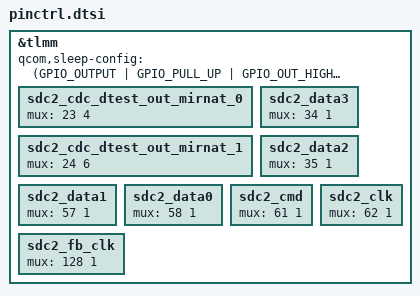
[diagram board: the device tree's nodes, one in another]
#include "gpio-dt.h"

/**
 *
 * NOTE: Every Dev team has to uncomment the respective PIN configuratoin.
 *
 */
&tlmm {
  //qup0_se0_l0: qup0_se0_l0 {
  //  mux = <0 1>;
  //};
  //ibi_i3c_qup0_se0_sda: ibi_i3c_qup0_se0_sda {
  //  mux = <0 2>;
  //};
  //aoss_cti_debug_data0: aoss_cti_debug_data0 {
  //  mux = <0 3>;
  //};
  //qup0_se0_l1: qup0_se0_l1 {
  //  mux = <1 1>;
  //};
  //ibi_i3c_qup0_se0_scl: ibi_i3c_qup0_se0_scl {
  //  mux = <1 2>;
  //};
  //aoss_cti_debug_data1: aoss_cti_debug_data1 {
  //  mux = <1 3>;
  //};
  //qup0_se0_l2: qup0_se0_l2 {
  //  mux = <2 1>;
  //};
  //qup0_se0_l3: qup0_se0_l3 {
  //  mux = <3 1>;
  //};
  //qup0_se1_l0: qup0_se1_l0 {
  //  mux = <4 1>;
  //};
  //ibi_i3c_qup0_se1_sda: ibi_i3c_qup0_se1_sda {
  //  mux = <4 2>;
  //};
  //aoss_cti_debug_data2: aoss_cti_debug_data2 {
  //  mux = <4 3>;
  //};
  //sd_write_protect: sd_write_protect {
  //  mux = <4 4>;
  //};
  //qdss_cti_trig0_in_mirb: qdss_cti_trig0_in_mirb {
  //  mux = <4 5>;
  //};
  //qup0_se1_l1: qup0_se1_l1 {
  //  mux = <5 1>;
  //};
  //ibi_i3c_qup0_se1_scl: ibi_i3c_qup0_se1_scl {
  //  mux = <5 2>;
  //};
  //aoss_cti_debug_data3: aoss_cti_debug_data3 {
  //  mux = <5 3>;
  //};
  //qdss_cti_trig0_out_mirb: qdss_cti_trig0_out_mirb {
  //  mux = <5 4>;
  //};
  //qup0_se1_l2: qup0_se1_l2 {
  //  mux = <6 1>;
  //};
  //qdss_cti_trig1_out_mirb: qdss_cti_trig1_out_mirb {
  //  mux = <6 2>;
  //};
  //qup0_se1_l3: qup0_se1_l3 {
  //  mux = <7 1>;
  //};
  //qdss_cti_trig1_in_mirb: qdss_cti_trig1_in_mirb {
  //  mux = <7 2>;
  //};
  //qup0_se2_l0: qup0_se2_l0 {
  //  mux = <8 1>;
  //};
  //do_not_expose_qup3_qspi_data_0: do_not_expose_qup3_qspi_data_0 {
  //  mux = <8 2>;
  //};
  //dbg_bus_out_loca_31: dbg_bus_out_loca_31 {
  //  mux = <8 3>;
  //};
  //phase_flag_status_loc_31: phase_flag_status_loc_31 {
  //  mux = <8 4>;
  //};
  //qup0_se2_l1: qup0_se2_l1 {
  //  mux = <9 1>;
  //};
  //do_not_expose_qup3_qspi_data_1: do_not_expose_qup3_qspi_data_1 {
  //  mux = <9 2>;
  //};
  //dbg_bus_out_loca_30: dbg_bus_out_loca_30 {
  //  mux = <9 3>;
  //};
  //phase_flag_status_loc_30: phase_flag_status_loc_30 {
  //  mux = <9 4>;
  //};
  //qup0_se2_l2: qup0_se2_l2 {
  //  mux = <10 1>;
  //};
  //qspi_clk: qspi_clk {
  //  mux = <10 2>;
  //};
  //qup0_se2_l3: qup0_se2_l3 {
  //  mux = <11 1>;
  //};
  //qspi_cs_n_0: qspi_cs_n_0 {
  //  mux = <11 2>;
  //};
  //dbg_bus_out_loca_29: dbg_bus_out_loca_29 {
  //  mux = <11 3>;
  //};
  //phase_flag_status_loc_29: phase_flag_status_loc_29 {
  //  mux = <11 4>;
  //};  
  //qup0_se2_l4: qup0_se2_l4 {
  //  mux = <12 1>;
  //};
  //qspi_cs_n_1: qspi_cs_n_1 {
  //  mux = <12 2>;
  //};
  //mdp_vsync0_out: mdp_vsync0_out {
  //  mux = <12 3>;
  //};
  //mdp_vsync1_out: mdp_vsync1_out {
  //  mux = <12 4>;
  //};
  //dbg_bus_out_loca_29: dbg_bus_out_loca_28 {
  //  mux = <12 5>;
  //};
  //phase_flag_status_loc_29: phase_flag_status_loc_28 {
  //  mux = <12 6>;
  //};
  //qup0_se2_l5: qup0_se2_l5 {
  //  mux = <13 1>;
  //};
  //do_not_expose_qup3_qspi_data_2: do_not_expose_qup3_qspi_data_2 {
  //  mux = <13 2>;
  //};
  //dbg_bus_out_loca_27: dbg_bus_out_loca_27 {
  //  mux = <13 3>;
  //};
  //phase_flag_status_loc_27: phase_flag_status_loc_27 {
  //  mux = <13 4>;
  //};
  //qup0_se2_l6: qup0_se2_l6 {
  //  mux = <14 1>;
  //};
  //do_not_expose_qup3_qspi_data_3: do_not_expose_qup3_qspi_data_3 {
  //  mux = <14 2>;
  //};
  //dbg_bus_out_loca_26: dbg_bus_out_loca_26 {
  //  mux = <14 3>;
  //};
  //phase_flag_status_loc_26: phase_flag_status_loc_26 {
  //  mux = <14 4>;
  //};
  //qup0_se3_l0: qup0_se3_l0 {
  //  mux = <15 1>;
  //};
  //i2s0_sck: i2s0_sck {
  //  mux = <15 2>;
  //};
  //dbg_bus_out_loca_25: dbg_bus_out_loca_25 {
  //  mux = <15 3>;
  //};
  //phase_flag_status_loc_25: phase_flag_status_loc_25 {
  //  mux = <15 4>;
  //};
  //qup0_se3_l1: qup0_se3_l1 {
  //  mux = <16 1>;
  //};
  //i2s0_data0: i2s0_data0 {
  //  mux = <16 2>;
  //};
  //dbg_bus_out_loca_24: dbg_bus_out_loca_24 {
  //  mux = <16 3>;
  //};
  //phase_flag_status_loc_24: phase_flag_status_loc_24 {
  //  mux = <16 4>;
  //};
  //qup0_se3_l2: qup0_se3_l2 {
  //  mux = <17 1>;
  //};
  //i2s0_data1: i2s0_data1 {
  //  mux = <17 2>;
  //};
  //tsense_pwm1_out_mir: tsense_pwm1_out_mir {
  //  mux = <17 3>;
  //};
  //tsense_pwm2_out_mir: tsense_pwm2_out_mir {
  //  mux = <17 4>;
  //};
  //qup0_se3_l3: qup0_se3_l3 {
  //  mux = <18 1>;
  //};
  //i2s0_ws: i2s0_ws {
  //  mux = <18 2>;
  //};
  //dbg_bus_out_loca_23: dbg_bus_out_loca_23 {
  //  mux = <18 3>;
  //};
  //phase_flag_status_loc_23: phase_flag_status_loc_23 {
  //  mux = <18 4>;
  //};
  //qup0_se4_l0: qup0_se4_l0 {
  //  mux = <19 1>;
  //};
  //mdp_vsync_s_mira: mdp_vsync_s_mira {
  //  mux = <19 2>;
  //};
  //gp_pdm_mira_0: gp_pdm_mira_0 {
  //  mux = <19 3>;
  //};
  //dbg_bus_out_locb_30: dbg_bus_out_locb_30 {
  //  mux = <19 4>;
  //};
  //qup0_se4_l1: qup0_se4_l1 {
  //  mux = <20 1>;
  //};
  //gp_pdm_mira_1: gp_pdm_mira_1 {
  //  mux = <20 2>;
  //};
  //dbg_bus_out_locb_11: dbg_bus_out_locb_11 {
  //  mux = <20 3>;
  //};
  //qup0_se4_l2: qup0_se4_l2 {
  //  mux = <21 1>;
  //};
  //gp_pdm_mira_2: gp_pdm_mira_2 {
  //  mux = <21 2>;
  //};
  //dbg_bus_out_locb_15: dbg_bus_out_locb_15 {
  //  mux = <21 3>;
  //};
  //qup0_se4_l3: qup0_se4_l3 {
  //  mux = <22 1>;
  //};
  //dbg_bus_out_locb_14: dbg_bus_out_locb_14 {
  //  mux = <22 2>;
  //};
  //qup0_se5_l0: qup0_se5_l0 {
  //  mux = <23 1>;
  //};
  //qup0_se3_l4: qup0_se3_l4 {
  //  mux = <23 2>;
  //};
  //audio_ext_mclk0: audio_ext_mclk0 {
  //  mux = <23 3>;
  //};
  sdc2_cdc_dtest_out_mirnat_0: sdc2_cdc_dtest_out_mirnat_0 {
    mux = <23 4>;
  };
  //atest_usb0_testdataout0_mirnat_0: atest_usb0_testdataout0_mirnat_0 {
  //  mux = <23 5>;
  //};
  //ddr_pxi0_test_tri_mirnat: ddr_pxi0_test_tri_mirnat {
  //  mux = <23 6>;
  //};
  //qup0_se5_l1: qup0_se5_l1 {
  //  mux = <24 1>;
  //};
  //qup0_se3_l5: qup0_se3_l5 {
  //  mux = <24 2>;
  //};
  //audio_ext_mclk1: audio_ext_mclk1 {
  //  mux = <24 3>;
  //};
  //audio_ref_clk: audio_ref_clk {
  //  mux = <24 4>;
  //};
  //dbg_out_clk: dbg_out_clk {
  //  mux = <24 5>;
  //};
  sdc2_cdc_dtest_out_mirnat_1: sdc2_cdc_dtest_out_mirnat_1 {
    mux = <24 6>;
  };
  //atest_usb0_testdataout0_mirnat_1: atest_usb0_testdataout0_mirnat_1 {
  //  mux = <24 7>;
  //};
  //ddr_pxi0_test_done_mirnat: ddr_pxi0_test_done_mirnat {
  //  mux = <24 8>;
  //};
  //qup0_se5_l2: qup0_se5_l2 {
  //  mux = <25 1>;
  //};
  //dbg_bus_out_locb_10: dbg_bus_out_locb_10 {
  //  mux = <25 2>;
  //};
  //qup0_se5_l3: qup0_se5_l3 {
  //  mux = <26 1>;
  //};
  //qup0_se3_l6: qup0_se3_l6 {
  //  mux = <26 2>;
  //};
  //pll_bist_sync: pll_bist_sync {
  //  mux = <26 3>;
  //};
  //dbg_bus_out_loca: dbg_bus_out_loca {
  //  mux = <26 4>;
  //};
  //phase_flag_status_loc: phase_flag_status_loc {
  //  mux = <26 5>;
  //};
  //qup0_se6_l0: qup0_se6_l0 {
  //  mux = <27 1>;
  //};
  //gp_mn: gp_mn {
  //  mux = <27 2>;
  //};
  //qup0_se6_l1: qup0_se6_l1 {
  //  mux = <28 1>;
  //};
  //gcc_gp2_clk_mirb: gcc_gp2_clk_mirb {
  //  mux = <28 2>;
  //};
  //qup0_se6_l2: qup0_se6_l2 {
  //  mux = <29 1>;
  //};
  //gcc_gp1_clk_mira: gcc_gp1_clk_mira {
  //  mux = <29 2>;
  //};
  //dbg_bus_out_locb_16: dbg_bus_out_locb_16 {
  //  mux = <29 3>;
  //};
  //qup0_se6_l3: qup0_se6_l3 {
  //  mux = <30 1>;
  //};
  //gcc_gp2_clk_mira: gcc_gp2_clk_mira {
  //  mux = <30 2>;
  //};
  //dbg_bus_out_locb_17: dbg_bus_out_locb_17 {
  //  mux = <30 3>;
  //};
  //qup0_se6_l4: qup0_se6_l4 {
  //  mux = <31 1>;
  //};
  //gcc_gp3_clk_mira: gcc_gp3_clk_mira {
  //  mux = <31 2>;
  //};
  //dbg_bus_out_locb_18: dbg_bus_out_locb_18 {
  //  mux = <31 3>;
  //};
  //qup1_se0_l0: qup1_se0_l0 {
  //  mux = <32 1>;
  //};
  //ibi_i3c_qup1_se0_sda: ibi_i3c_qup1_se0_sda {
  //  mux = <32 2>;
  //};
  //gcc_gp1_clk_mirb: gcc_gp1_clk_mirb {
  //  mux = <32 3>;
  //};
  //dbg_bus_out_locb: dbg_bus_out_locb {
  //  mux = <32 4>;
  //};
  //qup1_se0_l1: qup1_se0_l1 {
  //  mux = <33 1>;
  //};
  //ibi_i3c_qup1_se0_scl: ibi_i3c_qup1_se0_scl {
  //  mux = <33 2>;
  //};
  //gcc_gp3_clk_mirb: gcc_gp3_clk_mirb {
  //  mux = <33 3>;
  //};
  sdc2_data3: sdc2_data3 {
    mux = <34 1>;
  };
  sdc2_data2: sdc2_data2 {
    mux = <35 1>;
  };
  //qup1_se1_l0: qup1_se1_l0 {
  //  mux = <36 1>;
  //};
  //qup1_se2_l4: qup1_se2_l4 {
  //  mux = <36 2>;
  //};
  //qup1_se2_l4: qup1_se2_l4 {
  //  mux = <36 3>;
  //};
  //ibi_i3c_qup1_se1_sda: ibi_i3c_qup1_se1_sda {
  //  mux = <36 4>;
  //};
  //qup1_se1_l1: qup1_se1_l1 {
  //  mux = <37 1>;
  //};
  //qup1_se2_l5: qup1_se2_l5 {
  //  mux = <37 2>;
  //};
  //ibi_i3c_qup1_se1_scl: ibi_i3c_qup1_se1_scl {
  //  mux = <37 3>;
  //};
  //mdp_vsync_s_mirb: mdp_vsync_s_mirb {
  //  mux = <37 4>;
  //};
  //qup1_se1_l2: qup1_se1_l2 {
  //  mux = <38 1>;
  //};
  //qup1_se2_l6: qup1_se2_l6 {
  //  mux = <38 2>;
  //};
  //dbg_bus_out_loca_21: dbg_bus_out_loca_21 {
  //  mux = <38 3>;
  //};
  //phase_flag_status_loc_21: phase_flag_status_loc_21 {
  //  mux = <38 4>;
  //};
  //qup1_se1_l3: qup1_se1_l3 {
  //  mux = <39 1>;
  //};
  //dbg_bus_out_loca: dbg_bus_out_loca {
  //  mux = <39 3>;
  //};
  //phase_flag_status_loc: phase_flag_status_loc {
  //  mux = <39 4>;
  //};
  //qup1_se2_l0: qup1_se2_l0 {
  //  mux = <40 1>;
  //};
  //mdp_vsync2_out: mdp_vsync2_out {
  //  mux = <40 2>;
  //};
  //mdp_vsync3_out: mdp_vsync3_out {
  //  mux = <40 3>;
  //};
  //dbg_bus_out_loca_19: dbg_bus_out_loca_19 {
  //  mux = <40 4>;
  //};
  //phase_flag_status_loc_19: phase_flag_status_loc_19 {
  //  mux = <40 5>;
  //};
  //qdss_gpio_tracedata_loca_0: qdss_gpio_tracedata_loca_0 {
  //  mux = <40 6>;
  //};
  //qup1_se2_l1: qup1_se2_l1 {
  //  mux = <41 1>;
  //};
  //dbg_bus_out_loca_18: dbg_bus_out_loca_18 {
  //  mux = <41 2>;
  //};
  //phase_flag_status_loc_18: phase_flag_status_loc_18 {
  //  mux = <41 3>;
  //};
  //qdss_gpio_tracedata_loca_1: qdss_gpio_tracedata_loca_1 {
  //  mux = <41 4>;
  //};
  //qup1_se2_l2: qup1_se2_l2 {
  //  mux = <42 1>;
  //};
  //dbg_bus_out_loca_17: dbg_bus_out_loca_17 {
  //  mux = <42 2>;
  //};
  //phase_flag_status_loc_17: phase_flag_status_loc_17 {
  //  mux = <42 3>;
  //};
  //qdss_gpio_tracedata_loca_2: qdss_gpio_tracedata_loca_2 {
  //  mux = <42 4>;
  //};
  //qup1_se2_l3: qup1_se2_l3 {
  //  mux = <43 1>;
  //};
  //gp_pdm_mirb_0: gp_pdm_mirb_0 {
  //  mux = <43 2>;
  //};
  //dbg_bus_out_loca_16: dbg_bus_out_loca_16 {
  //  mux = <43 3>;
  //};
  //phase_flag_status_loc_16: phase_flag_status_loc_16 {
  //  mux = <43 4>;
  //};
  //qdss_gpio_tracedata_loca_3: qdss_gpio_tracedata_loca_3 {
  //  mux = <43 5>;
  //};
  //gp_pdm_mirb_1: gp_pdm_mirb_1 {
  //  mux = <44 1>;
  //};
  //dbg_bus_out_loca_15: dbg_bus_out_loca_15 {
  //  mux = <44 2>;
  //};
  //phase_flag_status_loc_15: phase_flag_status_loc_15 {
  //  mux = <44 3>;
  //};
  //qdss_cti_trig0_in_mira: qdss_cti_trig0_in_mira {
  //  mux = <44 4>;
  //};
  //atest_char_status_loc_0: atest_char_status_loc_0 {
  //  mux = <44 5>;
  //};
  //wcn_sw_ctrl: wcn_sw_ctrl {
  //  mux = <45 1>;
  //};
  //mdp_vsync_e: mdp_vsync_e {
  //  mux = <45 2>;
  //};
  //gp_pdm_mirb: gp_pdm_mirb {
  //  mux = <45 3>;
  //};
  //dbg_bus_out_loca: dbg_bus_out_loca {
  //  mux = <45 4>;
  //};
  //phase_flag_status_loc: phase_flag_status_loc {
  //  mux = <45 5>;
  //};
  //qdss_cti_trig1_in_mira: qdss_cti_trig1_in_mira {
  //  mux = <45 6>;
  //};
  //atest_char_status_loc: atest_char_status_loc {
  //  mux = <45 7>;
  //};
  //host2wlan_sol: host2wlan_sol {
  //  mux = <46 1>;
  //};
  //dbg_bus_out_loca_13: dbg_bus_out_loca_13 {
  //  mux = <46 2>;
  //};
  //phase_flag_status_loc_13: phase_flag_status_loc_13 {
  //  mux = <46 3>;
  //};
  //qdss_gpio_tracedata_loca_4: qdss_gpio_tracedata_loca_4 {
  //  mux = <46 4>;
  //};
  //atest_char_status_loc_2: atest_char_status_loc_2 {
  //  mux = <46 5>;
  //};
  //ddr_bist_stop: ddr_bist_stop {
  //  mux = <47 1>;
  //};
  //dbg_bus_out_loca_12: dbg_bus_out_loca_12 {
  //  mux = <47 2>;
  //};
  //phase_flag_status_loc_12: phase_flag_status_loc_12 {
  //  mux = <47 3>;
  //};
  //qdss_gpio_tracedata_loca_5: qdss_gpio_tracedata_loca_5 {
  //  mux = <47 4>;
  //};
  //atest_char_status_loc_3: atest_char_status_loc_3 {
  //  mux = <47 5>;
  //};
  //qup1_se4_l0: qup1_se4_l0 {
  //  mux = <48 1>;
  //};
  //dbg_bus_out_loca_11: dbg_bus_out_loca_11 {
  //  mux = <48 2>;
  //};
  //phase_flag_status_loc_11: phase_flag_status_loc_11 {
  //  mux = <48 3>;
  //};
  //qdss_gpio_tracedata_loca_6: qdss_gpio_tracedata_loca_6 {
  //  mux = <48 4>;
  //};
  //qup1_se4_l1: qup1_se4_l1 {
  //  mux = <49 1>;
  //};
  //dbg_bus_out_loca_10: dbg_bus_out_loca_10 {
  //  mux = <49 2>;
  //};
  //phase_flag_status_loc_10: phase_flag_status_loc_10 {
  //  mux = <49 3>;
  //};
  //qdss_gpio_tracedata_loca_7: qdss_gpio_tracedata_loca_7 {
  //  mux = <49 4>;
  //};
  //qup1_se4_l2: qup1_se4_l2 {
  //  mux = <50 1>;
  //};
  //qdss_gpio_tracedata_loca_8: qdss_gpio_tracedata_loca_8 {
  //  mux = <50 2>;
  //};
  //ddr_pxi1_test_tri_mirnat: ddr_pxi1_test_tri_mirnat {
  //  mux = <50 3>;
  //};
  //qup1_se4_l3: qup1_se4_l3 {
  //  mux = <51 1>;
  //};
  //qdss_gpio_tracedata_loca_9: qdss_gpio_tracedata_loca_9 {
  //  mux = <51 2>;
  //};
  //ddr_pxi1_test_done_mirnat: ddr_pxi1_test_done_mirnat {
  //  mux = <51 3>;
  //};
  //qup1_se4_l4: qup1_se4_l4 {
  //  mux = <52 1>;
  //};
  //wcn_sw_ctrl_wl_cx: wcn_sw_ctrl_wl_cx {
  //  mux = <52 2>;
  //};
  //qdss_gpio_tracedata_loca_10: qdss_gpio_tracedata_loca_10 {
  //  mux = <52 3>;
  //};
  //qup1_se4_l5: qup1_se4_l5 {
  //  mux = <53 1>;
  //};
  //qdss_gpio_tracedata_loca_11: qdss_gpio_tracedata_loca_11 {
  //  mux = <53 2>;
  //};
  //qup1_se4_l6: qup1_se4_l6 {
  //  mux = <54 1>;
  //};
  //qdss_cti_trig0_out_mira: qdss_cti_trig0_out_mira {
  //  mux = <54 2>;
  //};
  //qup1_se5_l0: qup1_se5_l0 {
  //  mux = <55 1>;
  //};
  //qup1_se6_l2_mira: qup1_se6_l2_mira {
  //  mux = <55 2>;
  //};
  //qup1_se5_l1: qup1_se5_l1 {
  //  mux = <56 1>;
  //};
  //qup1_se6_l3_mira: qup1_se6_l3_mira {
  //  mux = <56 2>;
  //};
  //vfr_0: vfr_0 {
  //  mux = <56 3>;
  //};
  //ddr_bist_fail: ddr_bist_fail {
  //  mux = <56 4>;
  //};
  sdc2_data1: sdc2_data1 {
    mux = <57 1>;
  };
  sdc2_data0: sdc2_data0 {
    mux = <58 1>;
  };
  //qup1_se6_l0: qup1_se6_l0 {
  //  mux = <59 1>;
  //};
  //grfc10: grfc10 {
  //  mux = <59 2>;
  //};
  //qup1_se5_l2: qup1_se5_l2 {
  //  mux = <59 3>;
  //};
  //qup1_se6_l1: qup1_se6_l1 {
  //  mux = <60 1>;
  //};
  //grfc11: grfc11 {
  //  mux = <60 2>;
  //};
  //qup1_se5_l3: qup1_se5_l3 {
  //  mux = <60 3>;
  //};
  //atest_usb0_atereset_mirnat: atest_usb0_atereset_mirnat {
  //  mux = <60 4>;
  //};
  sdc2_cmd: sdc2_cmd {
    mux = <61 1>;
  };
  sdc2_clk: sdc2_clk {
    mux = <62 1>;
  };
  //coex_uart1_tx: coex_uart1_tx {
  //  mux = <63 1>;
  //};
  //dbg_bus_out_loca_5: dbg_bus_out_loca_5 {
  //  mux = <63 2>;
  //};
  //phase_flag_status_loc_5: phase_flag_status_loc_5 {
  //  mux = <63 3>;
  //};
  //coex_uart1_rx: coex_uart1_rx {
  //  mux = <64 1>;
  //};
  //dbg_bus_out_loca_0: dbg_bus_out_loca_0 {
  //  mux = <64 2>;
  //};
  //phase_flag_status_loc_0: phase_flag_status_loc_0 {
  //  mux = <64 3>;
  //};
  //prng_rosc_test_out_0: prng_rosc_test_out_0 {
  //  mux = <66 1>;
  //};
  //dbg_bus_out_locb_26: dbg_bus_out_locb_26 {
  //  mux = <66 2>;
  //};
  //pcie0_clk_req_n: pcie0_clk_req_n {
  //  mux = <67 1>;
  //};
  //prng_rosc_test_out_1: prng_rosc_test_out_1 {
  //  mux = <67 2>;
  //};
  //dbg_bus_out_locb_24: dbg_bus_out_locb_24 {
  //  mux = <67 3>;
  //};
  //prng_rosc_test_out_2: prng_rosc_test_out_2 {
  //  mux = <68 1>;
  //};
  //dbg_bus_out_locb_27: dbg_bus_out_locb_27 {
  //  mux = <68 2>;
  //};
  //prng_rosc_test_out_3: prng_rosc_test_out_3 {
  //  mux = <69 1>;
  //};
  //dbg_bus_out_locb_9: dbg_bus_out_locb_9 {
  //  mux = <69 2>;
  //};
  //pcie1_clk_req_n: pcie1_clk_req_n {
  //  mux = <70 1>;
  //};
  //dbg_bus_out_locb_8: dbg_bus_out_locb_8 {
  //  mux = <70 2>;
  //};
  //dbg_bus_out_locb_7: dbg_bus_out_locb_7 {
  //  mux = <71 1>;
  //};
  //SDC1_RCLK: SDC1_RCLK {
  //  mux = <72 1>;
  //};
  //mdp_vsync_p_mirb: mdp_vsync_p_mirb {
  //  mux = <72 2>;
  //};
  //SDC1_DATA4: SDC1_DATA4 {
  //  mux = <73 1>;
  //};
  //SDC1_DATA5: SDC1_DATA5 {
  //  mux = <74 1>;
  //};
  //SDC1_DATA6: SDC1_DATA6 {
  //  mux = <75 1>;
  //};
  //dp0_hot_plug_detect: dp0_hot_plug_detect {
  //  mux = <75 2>;
  //};
  //SDC1_DATA7: SDC1_DATA7 {
  //  mux = <76 1>;
  //};
  //SDC1_CLK: SDC1_CLK {
  //  mux = <77 1>;
  //};
  //cci_timer0: cci_timer0 {
  //  mux = <77 2>;
  //};
  //SDC1_CMD: SDC1_CMD {
  //  mux = <78 1>;
  //};
  //tb_trig_sdc2: tb_trig_sdc2 {
  //  mux = <78 2>;
  //};
  //SDC1_DATA0: SDC1_DATA0 {
  //  mux = <79 1>;
  //};
  //SDC1_DATA1: SDC1_DATA1 {
  //  mux = <80 1>;
  //};
  //SDC1_DATA2: SDC1_DATA2 {
  //  mux = <81 1>;
  //};
  //SDC1_DATA3: SDC1_DATA3 {
  //  mux = <82 1>;
  //};
  //cam_mclk0: cam_mclk0 {
  //  mux = <83 1>;
  //};
  //cci_timer1: cci_timer1 {
  //  mux = <83 2>;
  //};
  //tmess_prng_rosc_test_out_1: tmess_prng_rosc_test_out_1 {
  //  mux = <83 3>;
  //};
  //qdss_gpio_tracedata_loca_12: qdss_gpio_tracedata_loca_12 {
  //  mux = <83 4>;
  //};
  //cam_mclk1: cam_mclk1 {
  //  mux = <84 1>;
  //};
  //cci_timer2: cci_timer2 {
  //  mux = <84 2>;
  //};
  //tmess_prng_rosc_test_out_2: tmess_prng_rosc_test_out_2 {
  //  mux = <84 3>;
  //};
  //qdss_gpio_tracedata_loca_13: qdss_gpio_tracedata_loca_13 {
  //  mux = <84 4>;
  //};
  //cam_mclk2: cam_mclk2 {
  //  mux = <85 1>;
  //};
  //cci_timer3: cci_timer3 {
  //  mux = <85 2>;
  //};
  //tmess_prng_rosc_test_out_3: tmess_prng_rosc_test_out_3 {
  //  mux = <85 3>;
  //};
  //qdss_gpio_tracedata_loca_14: qdss_gpio_tracedata_loca_14 {
  //  mux = <85 4>;
  //};
  //cam_mclk3: cam_mclk3 {
  //  mux = <86 1>;
  //};
  //cci_async_in0: cci_async_in0 {
  //  mux = <86 2>;
  //};
  //tmess_prng_rosc_test_out_0: tmess_prng_rosc_test_out_0 {
  //  mux = <86 3>;
  //};
  //qdss_gpio_tracedata_loca_15: qdss_gpio_tracedata_loca_15 {
  //  mux = <86 4>;
  //};
  //cam_mclk4: cam_mclk4 {
  //  mux = <87 1>;
  //};
  //tb_trig_sdc1: tb_trig_sdc1 {
  //  mux = <87 2>;
  //};
  //tgu_ch0_trigout: tgu_ch0_trigout {
  //  mux = <87 3>;
  //};
  //qdss_cti_trig1_out_mira: qdss_cti_trig1_out_mira {
  //  mux = <87 4>;
  //};
  //cci_i2c_sda0: cci_i2c_sda0 {
  //  mux = <88 1>;
  //};
  //tgu_ch1_trigout: tgu_ch1_trigout {
  //  mux = <88 2>;
  //};
  //dbg_bus_out_locb_6: dbg_bus_out_locb_6 {
  //  mux = <88 3>;
  //};
  //qdss_gpio_tracectl_loca: qdss_gpio_tracectl_loca {
  //  mux = <88 4>;
  //};
  //cci_i2c_scl0: cci_i2c_scl0 {
  //  mux = <89 1>;
  //};
  //dbg_bus_out_locb_5: dbg_bus_out_locb_5 {
  //  mux = <89 2>;
  //};
  //qdss_gpio_traceclk_loca: qdss_gpio_traceclk_loca {
  //  mux = <89 3>;
  //};
  //cci_i2c_sda1: cci_i2c_sda1 {
  //  mux = <90 1>;
  //};
  //qup1_se6_l2_mirb: qup1_se6_l2_mirb {
  //  mux = <90 2>;
  //};
  //dbg_bus_out_locb_4: dbg_bus_out_locb_4 {
  //  mux = <90 3>;
  //};
  //cci_i2c_scl1: cci_i2c_scl1 {
  //  mux = <91 1>;
  //};
  //qup1_se6_l3_mirb: qup1_se6_l3_mirb {
  //  mux = <91 2>;
  //};
  //dbg_bus_out_locb_3: dbg_bus_out_locb_3 {
  //  mux = <91 3>;
  //};
  //cci_i2c_sda2: cci_i2c_sda2 {
  //  mux = <92 1>;
  //};
  //qup1_se3_l0: qup1_se3_l0 {
  //  mux = <92 2>;
  //};
  //dbg_bus_out_locb_2: dbg_bus_out_locb_2 {
  //  mux = <92 3>;
  //};
  //cci_i2c_scl2: cci_i2c_scl2 {
  //  mux = <93 1>;
  //};
  //qup1_se3_l1: qup1_se3_l1 {
  //  mux = <93 2>;
  //};
  //dbg_bus_out_locb_1: dbg_bus_out_locb_1 {
  //  mux = <93 3>;
  //};
  //cci_i2c_sda3: cci_i2c_sda3 {
  //  mux = <94 1>;
  //};
  //qup1_se3_l2: qup1_se3_l2 {
  //  mux = <94 2>;
  //};
  //qup1_se0_l2: qup1_se0_l2 {
  //  mux = <94 3>;
  //};
  //dbg_bus_out_locb_0: dbg_bus_out_locb_0 {
  //  mux = <94 4>;
  //};
  //vsense_trigger_mirnat: vsense_trigger_mirnat {
  //  mux = <94 5>;
  //};
  //cci_i2c_scl3: cci_i2c_scl3 {
  //  mux = <95 1>;
  //};
  //qup1_se3_l3: qup1_se3_l3 {
  //  mux = <95 2>;
  //};
  //qup1_se0_l3: qup1_se0_l3 {
  //  mux = <95 3>;
  //};
  //uim0_data: uim0_data {
  //  mux = <96 1>;
  //};
  //uim0_clk: uim0_clk {
  //  mux = <97 1>;
  //};
  //uim0_reset: uim0_reset {
  //  mux = <98 1>;
  //};
  //uim0_present: uim0_present {
  //  mux = <99 1>;
  //};
  //uim1_data_mirb: uim1_data_mirb {
  //  mux = <100 1>;
  //};
  //uim1_clk_mirb: uim1_clk_mirb {
  //  mux = <101 1>;
  //};
  //uim1_reset_mirb: uim1_reset_mirb {
  //  mux = <102 1>;
  //};
  //uim1_present_mirb: uim1_present_mirb {
  //  mux = <103 1>;
  //};
  //qlink0_request: qlink0_request {
  //  mux = <104 1>;
  //};
  //qlink0_enable: qlink0_enable {
  //  mux = <105 1>;
  //};
  //qlink0_wmss_reset_n: qlink0_wmss_reset_n {
  //  mux = <106 1>;
  //};
  //qlink1_request: qlink1_request {
  //  mux = <107 1>;
  //};
  //qlink1_enable: qlink1_enable {
  //  mux = <108 1>;
  //};
  //qlink1_wmss_reset_n: qlink1_wmss_reset_n {
  //  mux = <109 1>;
  //};
  //uim1_data_mira: uim1_data_mira {
  //  mux = <110 1>;
  //};
  //uim1_clk_mira: uim1_clk_mira {
  //  mux = <111 1>;
  //};
  //uim1_reset_mira: uim1_reset_mira {
  //  mux = <112 1>;
  //};
  //uim1_present_mira: uim1_present_mira {
  //  mux = <113 1>;
  //};
  //rffe0_clk: rffe0_clk {
  //  mux = <114 1>;
  //};
  //grfc0: grfc0 {
  //  mux = <114 2>;
  //};
  //rffe0_data: rffe0_data {
  //  mux = <115 1>;
  //};
  //grfc1: grfc1 {
  //  mux = <115 2>;
  //};
  //rffe1_clk: rffe1_clk {
  //  mux = <116 1>;
  //};
  //grfc2: grfc2 {
  //  mux = <116 2>;
  //};
  //rffe1_data: rffe1_data {
  //  mux = <117 1>;
  //};
  //grfc3: grfc3 {
  //  mux = <117 2>;
  //};
  //grfc4: grfc4 {
  //  mux = <118 1>;
  //};
  //rffe2_clk: rffe2_clk {
  //  mux = <118 2>;
  //};
  //grfc5: grfc5 {
  //  mux = <119 1>;
  //};
  //rffe2_data: rffe2_data {
  //  mux = <119 2>;
  //};
  //grfc6: grfc6 {
  //  mux = <120 1>;
  //};
  //rffe3_clk: rffe3_clk {
  //  mux = <120 2>;
  //};
  //grfc7: grfc7 {
  //  mux = <121 1>;
  //};
  //rffe3_data: rffe3_data {
  //  mux = <121 2>;
  //};
  //rffe4_clk: rffe4_clk {
  //  mux = <122 1>;
  //};
  //grfc8: grfc8 {
  //  mux = <122 2>;
  //};
  //rffe4_data: rffe4_data {
  //  mux = <123 1>;
  //};
  //grfc9: grfc9 {
  //  mux = <123 2>;
  //};
  //nav_gpio0: nav_gpio0 {
  //  mux = <124 1>;
  //};
  //nav_gpio1: nav_gpio1 {
  //  mux = <125 1>;
  //};
  //grfc0_mira: grfc0_mira {
  //  mux = <126 1>;
  //};
  //nav_gpio2: nav_gpio2 {
  //  mux = <126 2>;
  //};
  //vfr_1: vfr_1 {
  //  mux = <126 3>;
  //};
  //grfc12: grfc12 {
  //  mux = <127 1>;
  //};
  //dbg_bus_out_loca_9: dbg_bus_out_loca_9 {
  //  mux = <127 2>;
  //};
  //phase_flag_status_loc_9: phase_flag_status_loc_9 {
  //  mux = <127 3>;
  //};
  sdc2_fb_clk: sdc2_fb_clk {
    mux = <128 1>;
  };
  //mdp_vsync_p_mira: mdp_vsync_p_mira {
  //  mux = <130 1>;
  //};
  //usb0_phy_ps: usb0_phy_ps {
  //  mux = <131 1>;
  //};
  //ddr_bist_start: ddr_bist_start {
  //  mux = <133 1>;
  //};
  //dbg_bus_out_loca_8: dbg_bus_out_loca_8 {
  //  mux = <138 1>;
  //};
  //phase_flag_status_loc_8: phase_flag_status_loc_8 {
  //  mux = <138 2>;
  //};
  //qdss_gpio_tracedata_locb_12: qdss_gpio_tracedata_locb_12 {
  //  mux = <138 3>;
  //};
  //dbg_bus_out_loca_7: dbg_bus_out_loca_7 {
  //  mux = <139 1>;
  //};
  //phase_flag_status_loc_7: phase_flag_status_loc_7 {
  //  mux = <139 2>;
  //};
  //qdss_gpio_tracedata_locb_13: qdss_gpio_tracedata_locb_13 {
  //  mux = <139 3>;
  //};
  //dbg_bus_out_loca_6: dbg_bus_out_loca_6 {
  //  mux = <140 1>;
  //};
  //phase_flag_status_loc_6: phase_flag_status_loc_6 {
  //  mux = <140 2>;
  //};
  //qdss_gpio_tracedata_locb_14: qdss_gpio_tracedata_locb_14 {
  //  mux = <140 3>;
  //};
  //jitter_bist_ref_clk: jitter_bist_ref_clk {
  //  mux = <141 1>;
  //};
  //qdss_gpio_tracedata_locb_15: qdss_gpio_tracedata_locb_15 {
  //  mux = <141 2>;
  //};
  //dbg_bus_out_loca_4: dbg_bus_out_loca_4 {
  //  mux = <142 1>;
  //};
  //phase_flag_status_loc_4: phase_flag_status_loc_4 {
  //  mux = <142 2>;
  //};
  //dbg_bus_out_loca_3: dbg_bus_out_loca_3 {
  //  mux = <143 1>;
  //};
  //phase_flag_status_loc_3: phase_flag_status_loc_3 {
  //  mux = <143 2>;
  //};
  //dbg_bus_out_loca_1: dbg_bus_out_loca_1 {
  //  mux = <144 1>;
  //};
  //phase_flag_status_loc_1: phase_flag_status_loc_1 {
  //  mux = <144 2>;
  //};
  //dbg_bus_out_locb_29: dbg_bus_out_locb_29 {
  //  mux = <145 1>;
  //};
  //dbg_bus_out_loca_2: dbg_bus_out_loca_2 {
  //  mux = <147 1>;
  //};
  //phase_flag_status_loc_2: phase_flag_status_loc_2 {
  //  mux = <147 2>;
  //};
  //dbg_bus_out_locb_13: dbg_bus_out_locb_13 {
  //  mux = <149 1>;
  //};
  //qdss_gpio_tracedata_locb_10: qdss_gpio_tracedata_locb_10 {
  //  mux = <149 2>;
  //};
  //sdc1_cdc_dtest_out_mirnat_0: sdc1_cdc_dtest_out_mirnat_0 {
  //  mux = <149 3>;
  //};
  //dbg_bus_out_locb_12: dbg_bus_out_locb_12 {
  //  mux = <150 1>;
  //};
  //qdss_gpio_tracedata_locb_11: qdss_gpio_tracedata_locb_11 {
  //  mux = <150 2>;
  //};
  //sdc1_cdc_dtest_out_mirnat_1: sdc1_cdc_dtest_out_mirnat_1 {
  //  mux = <150 3>;
  //};
  //sdc1_cdc_dtest_out_mir_1: sdc1_cdc_dtest_out_mir_1 {
  //  mux = <150 1>;
  //};
  //dbg_bus_out_locb_23: dbg_bus_out_locb_23 {
  //  mux = <151 1>;
  //};
  //dbg_bus_out_locb_22: dbg_bus_out_locb_22 {
  //  mux = <152 1>;
  //};
  //dbg_bus_out_locb_21: dbg_bus_out_locb_21 {
  //  mux = <153 1>;
  //};
  //dbg_bus_out_locb_20: dbg_bus_out_locb_20 {
  //  mux = <154 1>;
  //};
  //dbg_bus_out_locb_31: dbg_bus_out_locb_31 {
  //  mux = <155 1>;
  //};
  //qdss_gpio_traceclk_locb: qdss_gpio_traceclk_locb {
  //  mux = <155 2>;
  //};
  //dbg_bus_out_locb_28: dbg_bus_out_locb_28 {
  //  mux = <156 1>;
  //};
  //qdss_gpio_tracectl_locb: qdss_gpio_tracectl_locb {
  //  mux = <156 2>;
  //};
  //dbg_bus_out_locb_25: dbg_bus_out_locb_25 {
  //  mux = <157 1>;
  //};
  //qdss_gpio_tracedata_locb_0: qdss_gpio_tracedata_locb_0 {
  //  mux = <157 2>;
  //};
  //qdss_gpio_tracedata_locb_1: qdss_gpio_tracedata_locb_1 {
  //  mux = <158 1>;
  //};
  //qdss_gpio_tracedata_locb_2: qdss_gpio_tracedata_locb_2 {
  //  mux = <159 1>;
  //};
  //qdss_gpio_tracedata_locb_3: qdss_gpio_tracedata_locb_3 {
  //  mux = <160 1>;
  //};
  //qdss_gpio_tracedata_locb_4: qdss_gpio_tracedata_locb_4 {
  //  mux = <161 1>;
  //};
  //qdss_gpio_tracedata_locb_5: qdss_gpio_tracedata_locb_5 {
  //  mux = <162 1>;
  //};
  //qdss_gpio_tracedata_locb_6: qdss_gpio_tracedata_locb_6 {
  //  mux = <163 1>;
  //};
  //qdss_gpio_tracedata_locb_7: qdss_gpio_tracedata_locb_7 {
  //  mux = <164 1>;
  //};
  //qdss_gpio_tracedata_locb_8: qdss_gpio_tracedata_locb_8 {
  //  mux = <165 1>;
  //};
  //qdss_gpio_tracedata_locb_9: qdss_gpio_tracedata_locb_9 {
  //  mux = <166 1>;
  //};
};

&tlmm {
  qcom,sleep-config   =  <
(GPIO_OUTPUT | GPIO_PULL_UP | GPIO_OUT_HIGH | GPIO_PRG_YES)	/* GPIO_0 */
(GPIO_OUTPUT | GPIO_PULL_UP | GPIO_OUT_HIGH | GPIO_PRG_YES)	/* GPIO_1 */
(GPIO_INPUT | GPIO_PULL_DOWN | GPIO_OUT_LOW | GPIO_PRG_NO)	/* GPIO_2 */
(GPIO_INPUT | GPIO_PULL_DOWN | GPIO_OUT_LOW | GPIO_PRG_NO)	/* GPIO_3 */
(GPIO_OUTPUT | GPIO_PULL_UP | GPIO_OUT_HIGH | GPIO_PRG_YES)	/* GPIO_4 */
(GPIO_OUTPUT | GPIO_PULL_UP | GPIO_OUT_HIGH | GPIO_PRG_YES)	/* GPIO_5 */
(GPIO_INPUT  | GPIO_PULL_DOWN | GPIO_OUT_LOW | GPIO_PRG_NO)	/* GPIO_6 */
(GPIO_INPUT | GPIO_PULL_DOWN | GPIO_OUT_LOW | GPIO_PRG_NO)	/* GPIO_7 */
(GPIO_INPUT | GPIO_PULL_DOWN | GPIO_OUT_LOW | GPIO_PRG_NO)	/* GPIO_8 */

(GPIO_INPUT | GPIO_PULL_DOWN | GPIO_OUT_LOW | GPIO_PRG_NO)	/* GPIO_9 */
(GPIO_INPUT | GPIO_PULL_DOWN | GPIO_OUT_LOW | GPIO_PRG_NO)	/* GPIO_10 */
(GPIO_INPUT | GPIO_PULL_DOWN | GPIO_OUT_LOW | GPIO_PRG_NO)	/* GPIO_11 */
(GPIO_INPUT | GPIO_PULL_DOWN | GPIO_OUT_LOW | GPIO_PRG_NO)	/* GPIO_12 */
(GPIO_INPUT | GPIO_PULL_DOWN | GPIO_OUT_LOW | GPIO_PRG_NO)	/* GPIO_13 */
(GPIO_INPUT | GPIO_PULL_DOWN | GPIO_OUT_LOW | GPIO_PRG_NO)	/* GPIO_14 */
(GPIO_INPUT | GPIO_PULL_DOWN | GPIO_OUT_LOW | GPIO_PRG_NO)	/* GPIO_15 */
(GPIO_INPUT | GPIO_PULL_DOWN | GPIO_OUT_LOW | GPIO_PRG_NO)	/* GPIO_16 */
(GPIO_INPUT | GPIO_PULL_DOWN | GPIO_OUT_LOW | GPIO_PRG_NO)	/* GPIO_17 */
(GPIO_INPUT | GPIO_PULL_DOWN | GPIO_OUT_LOW | GPIO_PRG_NO)	/* GPIO_18 */

(GPIO_INPUT | GPIO_PULL_DOWN | GPIO_OUT_LOW | GPIO_PRG_NO)	/* GPIO_19 */
(GPIO_INPUT | GPIO_PULL_DOWN | GPIO_OUT_LOW | GPIO_PRG_NO)	/* GPIO_20 */
(GPIO_INPUT | GPIO_PULL_DOWN | GPIO_OUT_LOW | GPIO_PRG_NO)	/* GPIO_21 */
(GPIO_INPUT | GPIO_PULL_DOWN | GPIO_OUT_LOW | GPIO_PRG_NO)	/* GPIO_22 */
(GPIO_INPUT | GPIO_PULL_DOWN | GPIO_OUT_LOW | GPIO_PRG_NO)	/* GPIO_23 */
(GPIO_INPUT | GPIO_PULL_DOWN | GPIO_OUT_LOW | GPIO_PRG_NO)	/* GPIO_24 */
(GPIO_OUTPUT | GPIO_PULL_UP | GPIO_OUT_HIGH | GPIO_PRG_YES)	/* GPIO_25 */
(GPIO_INPUT | GPIO_PULL_DOWN | GPIO_OUT_LOW | GPIO_PRG_NO)	/* GPIO_26 */
(GPIO_OUTPUT | GPIO_PULL_UP | GPIO_OUT_HIGH | GPIO_PRG_YES)	/* GPIO_27 */
(GPIO_OUTPUT | GPIO_PULL_UP | GPIO_OUT_HIGH | GPIO_PRG_YES)	/* GPIO_28 */

(GPIO_OUTPUT | GPIO_PULL_UP | GPIO_OUT_HIGH | GPIO_PRG_YES)	/* GPIO_29 */
(GPIO_OUTPUT | GPIO_PULL_UP | GPIO_OUT_HIGH | GPIO_PRG_YES)	/* GPIO_30 */
(GPIO_INPUT | GPIO_PULL_DOWN | GPIO_OUT_LOW | GPIO_PRG_NO)	/* GPIO_31 */
(GPIO_OUTPUT | GPIO_PULL_UP | GPIO_OUT_HIGH | GPIO_PRG_YES)	/* GPIO_32 */
(GPIO_OUTPUT | GPIO_PULL_UP | GPIO_OUT_HIGH | GPIO_PRG_YES)	/* GPIO_33 */
(GPIO_INPUT | GPIO_PULL_DOWN | GPIO_OUT_LOW | GPIO_PRG_NO)	/* GPIO_34 */
(GPIO_INPUT | GPIO_PULL_DOWN | GPIO_OUT_LOW | GPIO_PRG_NO)	/* GPIO_35 */
(GPIO_INPUT | GPIO_PULL_DOWN | GPIO_OUT_LOW | GPIO_PRG_NO)	/* GPIO_36 */
(GPIO_INPUT | GPIO_PULL_DOWN | GPIO_OUT_LOW | GPIO_PRG_NO)	/* GPIO_37 */
(GPIO_INPUT | GPIO_PULL_DOWN | GPIO_OUT_LOW | GPIO_PRG_NO)	/* GPIO_38 */

(GPIO_INPUT | GPIO_PULL_DOWN | GPIO_OUT_LOW | GPIO_PRG_NO)	/* GPIO_39 */
(GPIO_INPUT | GPIO_PULL_DOWN | GPIO_OUT_LOW | GPIO_PRG_NO)	/* GPIO_40 */
(GPIO_INPUT | GPIO_PULL_DOWN | GPIO_OUT_LOW | GPIO_PRG_NO)	/* GPIO_41 */
(GPIO_INPUT | GPIO_PULL_DOWN | GPIO_OUT_LOW | GPIO_PRG_NO)	/* GPIO_42 */
(GPIO_INPUT | GPIO_PULL_DOWN | GPIO_OUT_LOW | GPIO_PRG_NO)	/* GPIO_43 */
(GPIO_INPUT | GPIO_PULL_DOWN | GPIO_OUT_LOW | GPIO_PRG_NO)	/* GPIO_44 */
(GPIO_INPUT | GPIO_PULL_DOWN | GPIO_OUT_LOW | GPIO_PRG_NO)	/* GPIO_45 */
(GPIO_INPUT | GPIO_PULL_DOWN | GPIO_OUT_LOW | GPIO_PRG_NO)	/* GPIO_46 */
(GPIO_INPUT | GPIO_PULL_DOWN | GPIO_OUT_LOW | GPIO_PRG_NO)	/* GPIO_47 */
(GPIO_INPUT | GPIO_PULL_DOWN | GPIO_OUT_LOW | GPIO_PRG_NO)	/* GPIO_48 */

(GPIO_INPUT | GPIO_PULL_DOWN | GPIO_OUT_LOW | GPIO_PRG_NO)	/* GPIO_49 */
(GPIO_OUTPUT | GPIO_PULL_UP | GPIO_OUT_HIGH | GPIO_PRG_YES)	/* GPIO_50 */
(GPIO_INPUT | GPIO_PULL_DOWN | GPIO_OUT_LOW | GPIO_PRG_NO)	/* GPIO_51 */
(GPIO_INPUT | GPIO_PULL_DOWN | GPIO_OUT_LOW | GPIO_PRG_NO)	/* GPIO_52 */
(GPIO_INPUT | GPIO_PULL_DOWN | GPIO_OUT_LOW | GPIO_PRG_NO)	/* GPIO_53 */
(GPIO_INPUT | GPIO_PULL_DOWN | GPIO_OUT_LOW | GPIO_PRG_NO)	/* GPIO_54 */
(GPIO_INPUT | GPIO_PULL_DOWN | GPIO_OUT_LOW | GPIO_PRG_NO)	/* GPIO_55 */
(GPIO_INPUT | GPIO_PULL_DOWN | GPIO_OUT_LOW | GPIO_PRG_NO)	/* GPIO_56 */
(GPIO_INPUT | GPIO_PULL_DOWN | GPIO_OUT_LOW | GPIO_PRG_NO)	/* GPIO_57 */
(GPIO_INPUT | GPIO_PULL_DOWN | GPIO_OUT_LOW | GPIO_PRG_NO)	/* GPIO_58 */

(GPIO_INPUT | GPIO_PULL_DOWN | GPIO_OUT_LOW | GPIO_PRG_NO)	/* GPIO_59 */
(GPIO_INPUT | GPIO_PULL_DOWN | GPIO_OUT_LOW | GPIO_PRG_NO)	/* GPIO_60 */
(GPIO_INPUT | GPIO_PULL_DOWN | GPIO_OUT_LOW | GPIO_PRG_NO)	/* GPIO_61 */
(GPIO_INPUT | GPIO_PULL_DOWN | GPIO_OUT_LOW | GPIO_PRG_NO)	/* GPIO_62 */
(GPIO_OUTPUT | GPIO_PULL_UP | GPIO_OUT_HIGH | GPIO_PRG_YES)	/* GPIO_63 */
(GPIO_INPUT | GPIO_NO_PULL | GPIO_OUT_LOW | GPIO_PRG_YES)   /* GPIO_64 */
(GPIO_INPUT | GPIO_NO_PULL | GPIO_OUT_LOW | GPIO_PRG_YES)	  /* GPIO_65 */
(GPIO_INPUT | GPIO_PULL_DOWN | GPIO_OUT_LOW | GPIO_PRG_NO)	/* GPIO_66 */
(GPIO_OUTPUT | GPIO_PULL_UP | GPIO_OUT_HIGH | GPIO_PRG_YES)	/* GPIO_67 */
(GPIO_OUTPUT | GPIO_PULL_UP | GPIO_OUT_HIGH | GPIO_PRG_YES)	/* GPIO_68 */

(GPIO_OUTPUT | GPIO_NO_PULL | GPIO_OUT_LOW | GPIO_PRG_YES)	/* GPIO_69 */
(GPIO_INPUT | GPIO_NO_PULL | GPIO_OUT_LOW | GPIO_PRG_YES)	  /* GPIO_70 */
(GPIO_OUTPUT | GPIO_NO_PULL | GPIO_OUT_LOW | GPIO_PRG_YES)	/* GPIO_71 */
(GPIO_INPUT | GPIO_PULL_DOWN | GPIO_OUT_LOW | GPIO_PRG_NO)	/* GPIO_72 */
(GPIO_INPUT | GPIO_NO_PULL | GPIO_OUT_LOW | GPIO_PRG_YES)	  /* GPIO_73 */
(GPIO_INPUT | GPIO_NO_PULL | GPIO_OUT_LOW | GPIO_PRG_YES)	  /* GPIO_74 */
(GPIO_INPUT | GPIO_PULL_DOWN | GPIO_OUT_LOW | GPIO_PRG_NO)	/* GPIO_75 */
(GPIO_INPUT | GPIO_PULL_DOWN | GPIO_OUT_LOW | GPIO_PRG_NO)	/* GPIO_76 */
(GPIO_INPUT | GPIO_PULL_DOWN | GPIO_OUT_LOW | GPIO_PRG_NO)	/* GPIO_77 */
(GPIO_INPUT | GPIO_PULL_DOWN | GPIO_OUT_LOW | GPIO_PRG_NO)	/* GPIO_78 */

(GPIO_INPUT | GPIO_PULL_DOWN | GPIO_OUT_LOW | GPIO_PRG_NO)	/* GPIO_79 */
(GPIO_INPUT | GPIO_PULL_DOWN | GPIO_OUT_LOW | GPIO_PRG_NO)	/* GPIO_80 */
(GPIO_INPUT | GPIO_PULL_DOWN | GPIO_OUT_LOW | GPIO_PRG_NO)	/* GPIO_81 */
(GPIO_INPUT | GPIO_NO_PULL | GPIO_OUT_LOW | GPIO_PRG_YES)	  /* GPIO_82 */
(GPIO_INPUT | GPIO_PULL_DOWN | GPIO_OUT_LOW | GPIO_PRG_NO)	/* GPIO_83 */
(GPIO_INPUT | GPIO_PULL_DOWN | GPIO_OUT_LOW | GPIO_PRG_NO)	/* GPIO_84 */
(GPIO_INPUT | GPIO_PULL_DOWN | GPIO_OUT_LOW | GPIO_PRG_NO)	/* GPIO_85 */
(GPIO_INPUT | GPIO_PULL_DOWN | GPIO_OUT_LOW | GPIO_PRG_NO)	/* GPIO_86 */
(GPIO_INPUT | GPIO_PULL_DOWN | GPIO_OUT_LOW | GPIO_PRG_NO)	/* GPIO_87 */

(GPIO_INPUT | GPIO_PULL_DOWN | GPIO_OUT_LOW | GPIO_PRG_NO)	/* GPIO_88 */
(GPIO_INPUT | GPIO_PULL_DOWN | GPIO_OUT_LOW | GPIO_PRG_NO)	/* GPIO_89 */
(GPIO_INPUT | GPIO_PULL_DOWN | GPIO_OUT_LOW | GPIO_PRG_NO)	/* GPIO_90 */
(GPIO_INPUT | GPIO_PULL_DOWN | GPIO_OUT_LOW | GPIO_PRG_NO)	/* GPIO_91 */
(GPIO_INPUT | GPIO_PULL_DOWN | GPIO_OUT_LOW | GPIO_PRG_NO)	/* GPIO_92 */
(GPIO_INPUT | GPIO_PULL_DOWN | GPIO_OUT_LOW | GPIO_PRG_NO)	/* GPIO_93 */
(GPIO_INPUT | GPIO_PULL_DOWN | GPIO_OUT_LOW | GPIO_PRG_NO)	/* GPIO_94 */
(GPIO_INPUT | GPIO_PULL_DOWN | GPIO_OUT_LOW | GPIO_PRG_NO)	/* GPIO_95 */
(GPIO_INPUT | GPIO_PULL_DOWN | GPIO_OUT_LOW | GPIO_PRG_NO)	/* GPIO_96 */
(GPIO_INPUT | GPIO_PULL_DOWN | GPIO_OUT_LOW | GPIO_PRG_NO)	/* GPIO_97 */

(GPIO_INPUT | GPIO_PULL_DOWN | GPIO_OUT_LOW | GPIO_PRG_NO)	/* GPIO_98 */
(GPIO_INPUT | GPIO_PULL_DOWN | GPIO_OUT_LOW | GPIO_PRG_NO)	/* GPIO_99 */
(GPIO_INPUT | GPIO_PULL_DOWN | GPIO_OUT_LOW | GPIO_PRG_NO)	/* GPIO_100 */
(GPIO_INPUT | GPIO_PULL_DOWN | GPIO_OUT_LOW | GPIO_PRG_NO)	/* GPIO_101 */
(GPIO_INPUT | GPIO_PULL_DOWN | GPIO_OUT_LOW | GPIO_PRG_NO)	/* GPIO_102 */
(GPIO_INPUT | GPIO_PULL_DOWN | GPIO_OUT_LOW | GPIO_PRG_NO)	/* GPIO_103 */
(GPIO_INPUT | GPIO_NO_PULL | GPIO_OUT_LOW | GPIO_PRG_YES)	  /* GPIO_104 */
(GPIO_INPUT | GPIO_NO_PULL | GPIO_OUT_LOW | GPIO_PRG_YES)	  /* GPIO_105 */
(GPIO_INPUT | GPIO_NO_PULL | GPIO_OUT_LOW | GPIO_PRG_YES)	  /* GPIO_106 */
(GPIO_INPUT | GPIO_NO_PULL | GPIO_OUT_LOW | GPIO_PRG_YES)	  /* GPIO_107 */

(GPIO_INPUT | GPIO_NO_PULL | GPIO_OUT_LOW | GPIO_PRG_YES)	  /* GPIO_108 */
(GPIO_INPUT | GPIO_NO_PULL | GPIO_OUT_LOW | GPIO_PRG_YES)	  /* GPIO_109 */
(GPIO_INPUT | GPIO_PULL_DOWN | GPIO_OUT_LOW | GPIO_PRG_NO)	/* GPIO_110 */
(GPIO_INPUT | GPIO_NO_PULL | GPIO_OUT_LOW | GPIO_PRG_YES)	  /* GPIO_111 */
(GPIO_INPUT | GPIO_NO_PULL | GPIO_OUT_LOW | GPIO_PRG_YES)	  /* GPIO_112 */
(GPIO_INPUT | GPIO_PULL_DOWN | GPIO_OUT_LOW | GPIO_PRG_NO)	/* GPIO_113 */
(GPIO_INPUT | GPIO_PULL_DOWN | GPIO_OUT_LOW | GPIO_PRG_NO)	/* GPIO_114 */
(GPIO_INPUT | GPIO_PULL_DOWN | GPIO_OUT_LOW | GPIO_PRG_NO)	/* GPIO_115 */
(GPIO_INPUT | GPIO_PULL_DOWN | GPIO_OUT_LOW | GPIO_PRG_NO)	/* GPIO_116 */
(GPIO_INPUT | GPIO_PULL_DOWN | GPIO_OUT_LOW | GPIO_PRG_NO)	/* GPIO_117 */

(GPIO_INPUT  | GPIO_NO_PULL | GPIO_OUT_LOW | GPIO_PRG_YES)	/* GPIO_118 */
(GPIO_OUTPUT | GPIO_NO_PULL | GPIO_OUT_LOW | GPIO_PRG_YES)	/* GPIO_119 */
(GPIO_INPUT | GPIO_NO_PULL | GPIO_OUT_LOW | GPIO_PRG_YES)	  /* GPIO_120 */
(GPIO_INPUT | GPIO_PULL_DOWN | GPIO_OUT_LOW | GPIO_PRG_NO)	/* GPIO_121 */
(GPIO_INPUT | GPIO_PULL_DOWN | GPIO_OUT_LOW | GPIO_PRG_NO)	/* GPIO_122 */
(GPIO_INPUT | GPIO_PULL_DOWN | GPIO_OUT_LOW | GPIO_PRG_NO)	/* GPIO_123 */
(GPIO_INPUT | GPIO_PULL_DOWN | GPIO_OUT_LOW | GPIO_PRG_NO)	/* GPIO_124 */
(GPIO_INPUT | GPIO_PULL_DOWN | GPIO_OUT_LOW | GPIO_PRG_NO)	/* GPIO_125 */
(GPIO_INPUT | GPIO_PULL_DOWN | GPIO_OUT_LOW | GPIO_PRG_NO)	/* GPIO_126 */
(GPIO_INPUT | GPIO_NO_PULL | GPIO_OUT_LOW | GPIO_PRG_YES)	  /* GPIO_127 */

(GPIO_INPUT | GPIO_PULL_DOWN | GPIO_OUT_LOW | GPIO_PRG_NO)	/* GPIO_128 */
(GPIO_INPUT | GPIO_PULL_DOWN | GPIO_OUT_LOW | GPIO_PRG_NO)	/* GPIO_129 */
(GPIO_INPUT | GPIO_PULL_DOWN | GPIO_OUT_LOW | GPIO_PRG_NO)	/* GPIO_130 */
(GPIO_INPUT | GPIO_PULL_DOWN | GPIO_OUT_LOW | GPIO_PRG_NO)	/* GPIO_131 */
(GPIO_INPUT | GPIO_PULL_DOWN | GPIO_OUT_LOW | GPIO_PRG_NO)	/* GPIO_132 */
(GPIO_INPUT | GPIO_PULL_DOWN | GPIO_OUT_LOW | GPIO_PRG_NO)	/* GPIO_133 */
(GPIO_INPUT | GPIO_PULL_DOWN | GPIO_OUT_LOW | GPIO_PRG_NO)	/* GPIO_134 */
(GPIO_INPUT | GPIO_PULL_DOWN | GPIO_OUT_LOW | GPIO_PRG_NO)	/* GPIO_135 */
(GPIO_INPUT | GPIO_PULL_DOWN | GPIO_OUT_LOW | GPIO_PRG_NO)	/* GPIO_136 */
(GPIO_INPUT | GPIO_PULL_DOWN | GPIO_OUT_LOW | GPIO_PRG_NO)	/* GPIO_137 */

(GPIO_INPUT | GPIO_PULL_DOWN | GPIO_OUT_LOW | GPIO_PRG_NO)	/* GPIO_138 */
(GPIO_INPUT | GPIO_PULL_DOWN | GPIO_OUT_LOW | GPIO_PRG_NO)	/* GPIO_139 */
(GPIO_INPUT | GPIO_PULL_DOWN | GPIO_OUT_LOW | GPIO_PRG_NO)	/* GPIO_140 */
(GPIO_INPUT | GPIO_PULL_DOWN | GPIO_OUT_LOW | GPIO_PRG_NO)	/* GPIO_141 */
(GPIO_INPUT | GPIO_PULL_DOWN | GPIO_OUT_LOW | GPIO_PRG_NO)	/* GPIO_142 */
(GPIO_INPUT | GPIO_PULL_DOWN | GPIO_OUT_LOW | GPIO_PRG_NO)	/* GPIO_143 */
(GPIO_INPUT | GPIO_PULL_DOWN | GPIO_OUT_LOW | GPIO_PRG_NO)	/* GPIO_144 */
(GPIO_INPUT | GPIO_PULL_DOWN | GPIO_OUT_LOW | GPIO_PRG_NO)	/* GPIO_145 */
(GPIO_INPUT | GPIO_PULL_DOWN | GPIO_OUT_LOW | GPIO_PRG_NO)	/* GPIO_146 */
(GPIO_INPUT | GPIO_PULL_DOWN | GPIO_OUT_LOW | GPIO_PRG_NO)	/* GPIO_147 */

(GPIO_INPUT | GPIO_PULL_DOWN | GPIO_OUT_LOW | GPIO_PRG_NO)	/* GPIO_148 */
(GPIO_INPUT | GPIO_PULL_DOWN | GPIO_OUT_LOW | GPIO_PRG_NO)	/* GPIO_149 */
(GPIO_INPUT | GPIO_PULL_DOWN | GPIO_OUT_LOW | GPIO_PRG_NO)	/* GPIO_150 */
(GPIO_INPUT | GPIO_KEEPER | GPIO_OUT_LOW | GPIO_PRG_NO)	    /* GPIO_151 */
(GPIO_INPUT | GPIO_KEEPER | GPIO_OUT_LOW | GPIO_PRG_NO)	    /* GPIO_152 */
(GPIO_INPUT | GPIO_NO_PULL | GPIO_OUT_LOW | GPIO_PRG_NO)	  /* GPIO_153 */
(GPIO_INPUT | GPIO_NO_PULL | GPIO_OUT_LOW | GPIO_PRG_NO)	  /* GPIO_154 */
(GPIO_INPUT | GPIO_KEEPER | GPIO_OUT_LOW | GPIO_PRG_NO)	    /* GPIO_155 */
(GPIO_INPUT | GPIO_KEEPER | GPIO_OUT_LOW | GPIO_PRG_NO)	    /* GPIO_156 */
(GPIO_INPUT | GPIO_KEEPER | GPIO_OUT_LOW | GPIO_PRG_NO)	    /* GPIO_157 */

(GPIO_INPUT | GPIO_KEEPER | GPIO_OUT_LOW | GPIO_PRG_NO)	    /* GPIO_158 */
(GPIO_INPUT | GPIO_NO_PULL | GPIO_OUT_LOW | GPIO_PRG_NO)	  /* GPIO_159 */
(GPIO_INPUT | GPIO_NO_PULL | GPIO_OUT_LOW | GPIO_PRG_NO)	  /* GPIO_160 */
(GPIO_INPUT | GPIO_PULL_DOWN | GPIO_OUT_LOW | GPIO_PRG_NO)	/* GPIO_161 */
(GPIO_INPUT | GPIO_PULL_DOWN | GPIO_OUT_LOW | GPIO_PRG_NO)	/* GPIO_162 */
(GPIO_INPUT | GPIO_PULL_UP | GPIO_OUT_HIGH | GPIO_PRG_NO)	  /* GPIO_163 */
(GPIO_INPUT | GPIO_PULL_DOWN | GPIO_OUT_LOW | GPIO_PRG_NO)	/* GPIO_164 */
(GPIO_INPUT | GPIO_PULL_UP | GPIO_OUT_HIGH | GPIO_PRG_NO)	  /* GPIO_165 */
(GPIO_INPUT | GPIO_PULL_DOWN | GPIO_OUT_LOW | GPIO_PRG_NO)	/* GPIO_166 */
  >;
};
